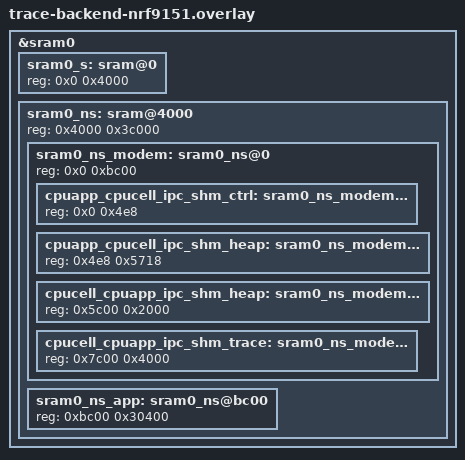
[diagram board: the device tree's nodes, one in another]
/*
 * Copyright (c) 2026 Nordic Semiconductor ASA
 *
 * SPDX-License-Identifier: LicenseRef-Nordic-5-Clause
 *
 */

/*
 * Application SRAM layout for nRF9151 DK with modem traces:
 *
 * 0x2000_4000  Non-secure RAM area          ( 240 kB)
 *   0x2000_4000  Modem shared area          (  47 kB)
 *     0x2000_4000  control                  (1256 B)
 *     0x2000_44e8  app -> cell              (22296 B)
 *     0x2000_9c00  cell -> app              (   8 kB)
 *     0x2000_bc00  trace                    ( 16 kB)
 *   0x2000_fc00  Application RAM            ( 193 kB)
 */

/delete-node/ &sram0_s;
/delete-node/ &sram0_ns;

&sram0 {

	sram0_s: sram@0 {
		reg = <0x0 0x4000>;
	};

	sram0_ns: sram@4000 {
		reg = <0x4000 0x3c000>;
		#address-cells = <1>;
		#size-cells = <1>;
		ranges = <0x0 0x4000 0x3c000>;

		/* Must be in first 128 kB of RAM. */
		sram0_ns_modem: sram0_ns@0 {
			/* Modem (shared) memory */
			reg = <0x0 0xbc00>;
			#address-cells = <1>;
			#size-cells = <1>;
			ranges = <0x0 0x0 0xbc00>;

			cpuapp_cpucell_ipc_shm_ctrl: sram0_ns_modem@0 {
				/* Modem IPC control */
				reg = <0x0 0x4e8>;
			};

			cpuapp_cpucell_ipc_shm_heap: sram0_ns_modem@4e8 {
				/* Modem IPC transmit */
				reg = <0x4e8 0x5718>;
			};

			cpucell_cpuapp_ipc_shm_heap: sram0_ns_modem@5c00 {
				/* Modem IPC receive */
				reg = <0x5c00 0x2000>;
			};

			cpucell_cpuapp_ipc_shm_trace: sram0_ns_modem@7c00 {
				/* Modem trace memory */
				reg = <0x7c00 0x4000>;
			};

		};

		sram0_ns_app: sram0_ns@bc00 {
			/* Non-Secure application memory */
			reg = <0xbc00 0x30400>;
		};
	};
};
